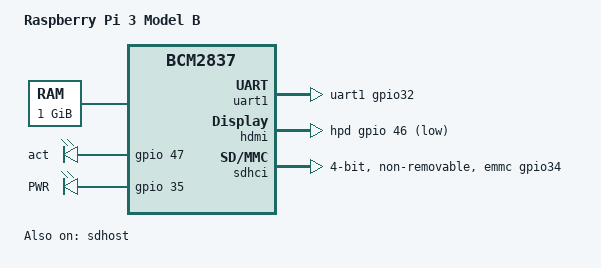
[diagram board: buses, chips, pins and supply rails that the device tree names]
/dts-v1/;
#include "bcm2837.dtsi"
#include "../../../../arm/boot/dts/bcm2835-rpi.dtsi"
#include "../../../../arm/boot/dts/bcm283x-rpi-smsc9514.dtsi"

/ {
	compatible = "raspberrypi,3-model-b", "brcm,bcm2837";
	model = "Raspberry Pi 3 Model B";

	memory {
		reg = <0 0x40000000>;
	};

	leds {
		act {
			gpios = <&gpio 47 0>;
		};

		pwr {
			label = "PWR";
			gpios = <&gpio 35 0>;
			default-state = "keep";
			linux,default-trigger = "default-on";
		};
	};
};

&uart1 {
	pinctrl-names = "default";
	pinctrl-0 = <&uart1_gpio32>;
	status = "okay";
};

&hdmi {
	hpd-gpios = <&gpio 46 GPIO_ACTIVE_LOW>;
};

/* SDHCI is used to control the SDIO for wireless */
&sdhci {
	pinctrl-names = "default";
	pinctrl-0 = <&emmc_gpio34>;
	status = "okay";
	bus-width = <4>;
	non-removable;
};

/* SDHOST is used to drive the SD card */
&sdhost {
	pinctrl-names = "default";
	pinctrl-0 = <&sdhost_gpio48>;
	status = "okay";
	bus-width = <4>;
};
